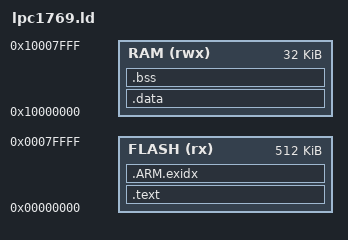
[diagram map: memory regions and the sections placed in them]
/* Mapa de memoria del LPC1769 (igual al que genera MCUXpresso). */
MEMORY
{
    FLASH (rx) : ORIGIN = 0x00000000, LENGTH = 512K
    RAM (rwx)  : ORIGIN = 0x10000000, LENGTH = 32K
}
ENTRY(Reset_Handler)
_vStackTop = ORIGIN(RAM) + LENGTH(RAM);
SECTIONS
{
    .text : {
        KEEP(*(.isr_vector))
        *(.text*) *(.rodata*)
        . = ALIGN(4);
    } > FLASH
    .ARM.exidx : { *(.ARM.exidx*) } > FLASH
    _etext = .;
    .data : AT(_etext) {
        _sdata = .;
        *(.data*)
        . = ALIGN(4);
        _edata = .;
    } > RAM
    .bss (NOLOAD) : {
        _sbss = .;
        *(.bss*) *(COMMON)
        . = ALIGN(4);
        _ebss = .;
    } > RAM
}
